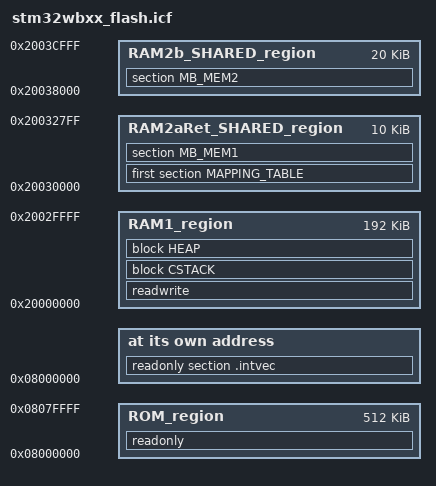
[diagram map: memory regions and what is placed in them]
/*-CPU Vector Table-*/
define symbol __ICFEDIT_intvec_start__ = 0x08000000;

/*-Memory Regions-*/
define symbol __ICFEDIT_region_ROM_start__ = 0x08000000;
define symbol __ICFEDIT_region_ROM_end__   = 0x0807FFFF;

define symbol __ICFEDIT_region_RAM1_start__ = 0x20000000;
define symbol __ICFEDIT_region_RAM1_end__   = 0x2002FFFF;

define symbol __ICFEDIT_region_RAM2aRet_SHARED_start__ = 0x20030000;
define symbol __ICFEDIT_region_RAM2aRet_SHARED_end__   = 0x200327FF;

define symbol __ICFEDIT_region_RAM2b_SHARED_start__ = 0x20038000;
define symbol __ICFEDIT_region_RAM2b_SHARED_end__   = 0x2003CFFF;


/*-Sizes-*/
define symbol __ICFEDIT_size_cstack__ = 0x2000;
define symbol __ICFEDIT_size_heap__   = 0x2000;

define memory mem with size = 4G;

define region ROM_region   = mem:[from __ICFEDIT_region_ROM_start__   to __ICFEDIT_region_ROM_end__];
define region RAM1_region   = mem:[from __ICFEDIT_region_RAM1_start__   to __ICFEDIT_region_RAM1_end__];
define region RAM2aRet_SHARED_region   = mem:[from __ICFEDIT_region_RAM2aRet_SHARED_start__   to __ICFEDIT_region_RAM2aRet_SHARED_end__];
define region RAM2b_SHARED_region   = mem:[from __ICFEDIT_region_RAM2b_SHARED_start__   to __ICFEDIT_region_RAM2b_SHARED_end__];

define block CSTACK    with alignment = 8, size = __ICFEDIT_size_cstack__   { };
define block HEAP      with alignment = 8, size = __ICFEDIT_size_heap__     { };

initialize by copy { readwrite };
do not initialize  { section .noinit,
                     section MAPPING_TABLE,
					 section MB_MEM1 };

place at address mem:__ICFEDIT_intvec_start__ { readonly section .intvec };

place in ROM_region   { readonly };
place in RAM1_region   { readwrite,
                        block CSTACK, block HEAP };
place in RAM2aRet_SHARED_region   { first section MAPPING_TABLE};
place in RAM2aRet_SHARED_region   { section MB_MEM1};
place in RAM2b_SHARED_region   	  { section MB_MEM2};
